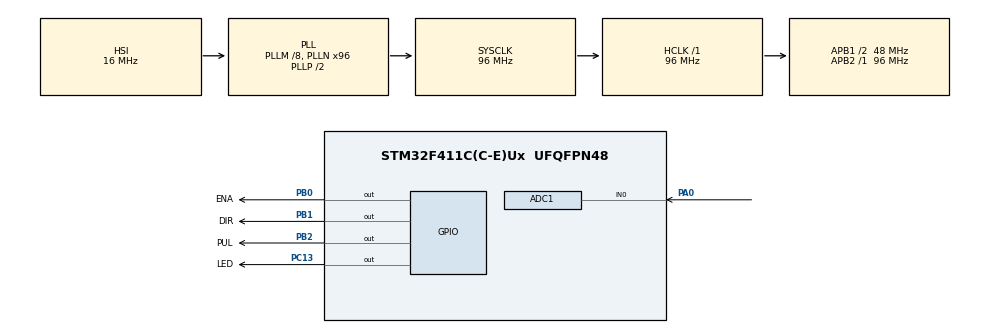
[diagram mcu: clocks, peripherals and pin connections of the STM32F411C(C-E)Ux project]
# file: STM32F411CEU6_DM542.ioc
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ADC1.Channel-0\#ChannelRegularConversion=ADC_CHANNEL_0
ADC1.NbrOfConversionFlag=1
ADC1.Rank-0\#ChannelRegularConversion=1
ADC1.SamplingTime-0\#ChannelRegularConversion=ADC_SAMPLETIME_3CYCLES
ADC1.master=1
Mcu.Family=STM32F4
Mcu.Name=STM32F411C(C-E)Ux
Mcu.Package=UFQFPN48
NVIC.PriorityGroup=NVIC_PRIORITYGROUP_4
PA0-WKUP.Signal=ADCx_IN0
PA13.Mode=Serial_Wire
PA13.Signal=SYS_JTMS-SWDIO
PA14.Mode=Serial_Wire
PA14.Signal=SYS_JTCK-SWCLK
PB0.GPIO_Label=ENA
PB0.Signal=GPIO_Output
PB1.GPIO_Label=DIR
PB1.Signal=GPIO_Output
PB2.GPIO_Label=PUL
PB2.Signal=GPIO_Output
PC13-ANTI_TAMP.GPIO_Label=LED
PC13-ANTI_TAMP.Signal=GPIO_Output
PH0\ -\ OSC_IN.Mode=HSE-External-Oscillator
PH0\ -\ OSC_IN.Signal=RCC_OSC_IN
PH1\ -\ OSC_OUT.Mode=HSE-External-Oscillator
PH1\ -\ OSC_OUT.Signal=RCC_OSC_OUT
ProjectManager.HeapSize=0x200
ProjectManager.StackSize=0x400
ProjectManager.TargetToolchain=STM32CubeIDE
RCC.48MHZClocksFreq_Value=48000000
RCC.AHBFreq_Value=96000000
RCC.APB1CLKDivider=RCC_HCLK_DIV2
RCC.APB1Freq_Value=48000000
RCC.APB1TimFreq_Value=96000000
RCC.APB2Freq_Value=96000000
RCC.APB2TimFreq_Value=96000000
RCC.CortexFreq_Value=96000000
RCC.HCLKFreq_Value=96000000
RCC.HSE_VALUE=25000000
RCC.HSI_VALUE=16000000
RCC.LSE_VALUE=32768
RCC.PLLM=8
RCC.PLLN=96
RCC.SYSCLKFreq_VALUE=96000000
RCC.SYSCLKSource=RCC_SYSCLKSOURCE_PLLCLK
RCC.VCOOutputFreq_Value=192000000
SH.ADCx_IN0.0=ADC1_IN0,IN0
TIM3.Prescaler=96-1
VP_TIM3_VS_ClockSourceINT.Mode=Internal
board=custom

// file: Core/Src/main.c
/* USER CODE BEGIN Header */
/**
  ******************************************************************************
  * @file           : main.c
  * @brief          : Main program body
  ******************************************************************************
  * @attention
  *
  * Copyright (c) 2025 STMicroelectronics.
  * All rights reserved.
  *
  * This software is licensed under terms that can be found in the LICENSE file
  * in the root directory of this software component.
  * If no LICENSE file comes with this software, it is provided AS-IS.
  *
  ******************************************************************************
  */
/* USER CODE END Header */
#include "main.h"

ADC_HandleTypeDef hadc1;

TIM_HandleTypeDef htim3;

void SystemClock_Config(void);
static void MX_GPIO_Init(void);
static void MX_TIM3_Init(void);
static void MX_ADC1_Init(void);

/* USER CODE BEGIN 0 */
void delay_us (uint16_t us)
{
	__HAL_TIM_SET_COUNTER(&htim3,0);  // set the counter value a 0
	while (__HAL_TIM_GET_COUNTER(&htim3) < us);  // wait for the counter to reach the us input in the parameter
}

uint32_t map(uint32_t au32_IN, uint32_t au32_INmin, uint32_t au32_INmax, uint32_t au32_OUTmin, uint32_t au32_OUTmax)
{
    return ((((au32_IN - au32_INmin)*(au32_OUTmax - au32_OUTmin))/(au32_INmax - au32_INmin)) + au32_OUTmin);
}
/* USER CODE END 0 */

int main(void)
{

  /* MCU Configuration--------------------------------------------------------*/

  /* Reset of all peripherals, Initializes the Flash interface and the Systick. */
  HAL_Init();

  /* Configure the system clock */
  SystemClock_Config();

  /* Initialize all configured peripherals */
  MX_GPIO_Init();
  MX_TIM3_Init();
  MX_ADC1_Init();
  /* USER CODE BEGIN 2 */
  HAL_TIM_Base_Start(&htim3);  // start the Timer1

  uint32_t delay_motor = 1000;

  HAL_GPIO_WritePin(ENA_GPIO_Port, ENA_Pin, GPIO_PIN_RESET);      // Керування силовою частиною драйвера
  HAL_GPIO_WritePin(DIR_GPIO_Port, DIR_Pin, GPIO_PIN_SET);        // Керування напрямком обертання
  /* USER CODE END 2 */

  /* Infinite loop */
  /* USER CODE BEGIN WHILE */
  while (1)
  {
    // Код для зчитування напргуи з потенціометра та ремап цього значення в значення затримки для мотора
//    HAL_ADC_Start(&hadc1);
//    HAL_ADC_PollForConversion(&hadc1, 100);
//    uint32_t ADC_VAL = HAL_ADC_GetValue(&hadc1) + 1;
//    HAL_ADC_Stop(&hadc1);
//    delay_motor = map(ADC_VAL, 1, 4096, 9000, 300);
//
//    if(ADC_VAL < 300){
//  	  HAL_GPIO_WritePin(ENA_GPIO_Port, ENA_Pin, GPIO_PIN_SET);
//    }
//
//    else{
//  	  HAL_GPIO_WritePin(ENA_GPIO_Port, ENA_Pin, GPIO_PIN_RESET);
//    }

    // Основний код для обертання мотором
	  HAL_GPIO_WritePin(PUL_GPIO_Port, PUL_Pin, GPIO_PIN_RESET);
	  delay_us(delay_motor);
	  HAL_GPIO_WritePin(PUL_GPIO_Port, PUL_Pin, GPIO_PIN_SET);
	  delay_us(delay_motor);
    /* USER CODE END WHILE */

  }
}

void SystemClock_Config(void)
{
  RCC_OscInitTypeDef RCC_OscInitStruct = {0};
  RCC_ClkInitTypeDef RCC_ClkInitStruct = {0};

  /** Configure the main internal regulator output voltage
  */
  __HAL_RCC_PWR_CLK_ENABLE();
  __HAL_PWR_VOLTAGESCALING_CONFIG(PWR_REGULATOR_VOLTAGE_SCALE1);

  /** Initializes the RCC Oscillators according to the specified parameters
  * in the RCC_OscInitTypeDef structure.
  */
  RCC_OscInitStruct.OscillatorType = RCC_OSCILLATORTYPE_HSI;
  RCC_OscInitStruct.HSIState = RCC_HSI_ON;
  RCC_OscInitStruct.HSICalibrationValue = RCC_HSICALIBRATION_DEFAULT;
  RCC_OscInitStruct.PLL.PLLState = RCC_PLL_ON;
  RCC_OscInitStruct.PLL.PLLSource = RCC_PLLSOURCE_HSI;
  RCC_OscInitStruct.PLL.PLLM = 8;
  RCC_OscInitStruct.PLL.PLLN = 96;
  RCC_OscInitStruct.PLL.PLLP = RCC_PLLP_DIV2;
  RCC_OscInitStruct.PLL.PLLQ = 4;
  if (HAL_RCC_OscConfig(&RCC_OscInitStruct) != HAL_OK)
  {
    Error_Handler();
  }

  /** Initializes the CPU, AHB and APB buses clocks
  */
  RCC_ClkInitStruct.ClockType = RCC_CLOCKTYPE_HCLK|RCC_CLOCKTYPE_SYSCLK
                              |RCC_CLOCKTYPE_PCLK1|RCC_CLOCKTYPE_PCLK2;
  RCC_ClkInitStruct.SYSCLKSource = RCC_SYSCLKSOURCE_PLLCLK;
  RCC_ClkInitStruct.AHBCLKDivider = RCC_SYSCLK_DIV1;
  RCC_ClkInitStruct.APB1CLKDivider = RCC_HCLK_DIV2;
  RCC_ClkInitStruct.APB2CLKDivider = RCC_HCLK_DIV1;

  if (HAL_RCC_ClockConfig(&RCC_ClkInitStruct, FLASH_LATENCY_3) != HAL_OK)
  {
    Error_Handler();
  }
}

static void MX_ADC1_Init(void)
{

  ADC_ChannelConfTypeDef sConfig = {0};

  /** Configure the global features of the ADC (Clock, Resolution, Data Alignment and number of conversion)
  */
  hadc1.Instance = ADC1;
  hadc1.Init.ClockPrescaler = ADC_CLOCK_SYNC_PCLK_DIV4;
  hadc1.Init.Resolution = ADC_RESOLUTION_12B;
  hadc1.Init.ScanConvMode = DISABLE;
  hadc1.Init.ContinuousConvMode = DISABLE;
  hadc1.Init.DiscontinuousConvMode = DISABLE;
  hadc1.Init.ExternalTrigConvEdge = ADC_EXTERNALTRIGCONVEDGE_NONE;
  hadc1.Init.ExternalTrigConv = ADC_SOFTWARE_START;
  hadc1.Init.DataAlign = ADC_DATAALIGN_RIGHT;
  hadc1.Init.NbrOfConversion = 1;
  hadc1.Init.DMAContinuousRequests = DISABLE;
  hadc1.Init.EOCSelection = ADC_EOC_SINGLE_CONV;
  if (HAL_ADC_Init(&hadc1) != HAL_OK)
  {
    Error_Handler();
  }

  /** Configure for the selected ADC regular channel its corresponding rank in the sequencer and its sample time.
  */
  sConfig.Channel = ADC_CHANNEL_0;
  sConfig.Rank = 1;
  sConfig.SamplingTime = ADC_SAMPLETIME_3CYCLES;
  if (HAL_ADC_ConfigChannel(&hadc1, &sConfig) != HAL_OK)
  {
    Error_Handler();
  }

}

static void MX_TIM3_Init(void)
{

  TIM_ClockConfigTypeDef sClockSourceConfig = {0};
  TIM_MasterConfigTypeDef sMasterConfig = {0};

  htim3.Instance = TIM3;
  htim3.Init.Prescaler = 96-1;
  htim3.Init.CounterMode = TIM_COUNTERMODE_UP;
  htim3.Init.Period = 65535;
  htim3.Init.ClockDivision = TIM_CLOCKDIVISION_DIV1;
  htim3.Init.AutoReloadPreload = TIM_AUTORELOAD_PRELOAD_DISABLE;
  if (HAL_TIM_Base_Init(&htim3) != HAL_OK)
  {
    Error_Handler();
  }
  sClockSourceConfig.ClockSource = TIM_CLOCKSOURCE_INTERNAL;
  if (HAL_TIM_ConfigClockSource(&htim3, &sClockSourceConfig) != HAL_OK)
  {
    Error_Handler();
  }
  sMasterConfig.MasterOutputTrigger = TIM_TRGO_RESET;
  sMasterConfig.MasterSlaveMode = TIM_MASTERSLAVEMODE_DISABLE;
  if (HAL_TIMEx_MasterConfigSynchronization(&htim3, &sMasterConfig) != HAL_OK)
  {
    Error_Handler();
  }

}

static void MX_GPIO_Init(void)
{
  GPIO_InitTypeDef GPIO_InitStruct = {0};

  /* GPIO Ports Clock Enable */
  __HAL_RCC_GPIOC_CLK_ENABLE();
  __HAL_RCC_GPIOH_CLK_ENABLE();
  __HAL_RCC_GPIOA_CLK_ENABLE();
  __HAL_RCC_GPIOB_CLK_ENABLE();

  /*Configure GPIO pin Output Level */
  HAL_GPIO_WritePin(LED_GPIO_Port, LED_Pin, GPIO_PIN_RESET);

  /*Configure GPIO pin Output Level */
  HAL_GPIO_WritePin(GPIOB, ENA_Pin|DIR_Pin|PUL_Pin, GPIO_PIN_RESET);

  /*Configure GPIO pin : LED_Pin */
  GPIO_InitStruct.Pin = LED_Pin;
  GPIO_InitStruct.Mode = GPIO_MODE_OUTPUT_PP;
  GPIO_InitStruct.Pull = GPIO_NOPULL;
  GPIO_InitStruct.Speed = GPIO_SPEED_FREQ_LOW;
  HAL_GPIO_Init(LED_GPIO_Port, &GPIO_InitStruct);

  /*Configure GPIO pins : ENA_Pin DIR_Pin PUL_Pin */
  GPIO_InitStruct.Pin = ENA_Pin|DIR_Pin|PUL_Pin;
  GPIO_InitStruct.Mode = GPIO_MODE_OUTPUT_PP;
  GPIO_InitStruct.Pull = GPIO_NOPULL;
  GPIO_InitStruct.Speed = GPIO_SPEED_FREQ_LOW;
  HAL_GPIO_Init(GPIOB, &GPIO_InitStruct);

}

void Error_Handler(void)
{
  __disable_irq();
  while (1)
  {
  }
}
